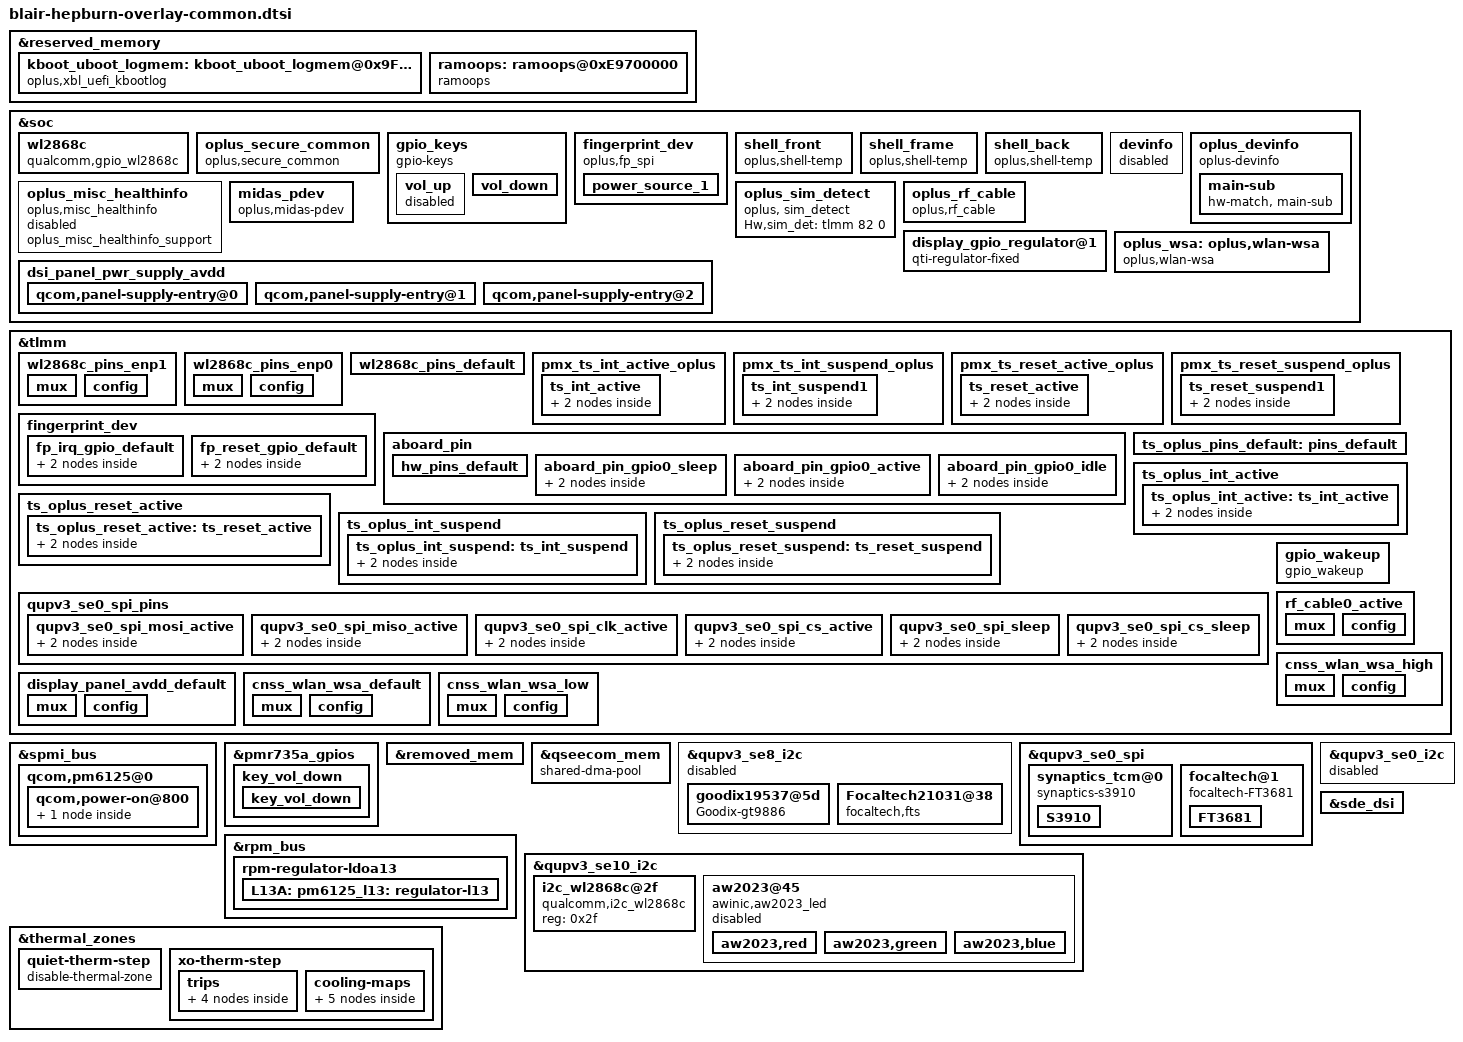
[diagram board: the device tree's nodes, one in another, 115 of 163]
#include "../qcom/blair-qrd-nopmi.dtsi"

/* #ifdef OPLUS_ARCH_EXTENDS */
#include "audio/blair-hepburn-audio.dtsi"
/* #endif OPLUS_ARCH_EXTENDS */
/* DTBO: Platform common generic overlay */

&reserved_memory {
	//xbl_uefi_mem address get from: PcdEmbeddedFdBaseAddress +
	//SERIAL_BUFFER_OFFSET = 0x9FC00000 + 0x3F7000 = 0x9FFF7000
	//kernel boot log: 0x9FE00000~ 0x9FFF6FFF, xbl-uefi log: 0x9FFF7000 ~ 0x9FFFFFFF
	kboot_uboot_logmem: kboot_uboot_logmem@0x9FE00000 {
		reg = <0x0 0x9FE00000 0x0 0x200000>;
		compatible = "oplus,xbl_uefi_kbootlog";
		xbluefi-offset = <0x1F7000>;
		no-map;
	};

	//#if IS_ENABLED(CONFIG_OPLUS_FEATURE_DUMP_DEVICE_INFO)
	ramoops: ramoops@0xE9700000 {
		compatible = "ramoops";
		reg = <0x0 0xE9700000 0x0 0x600000>;  //6M
		record-size  = <0x40000>; //256k
		console-size = <0x40000>; //256k
		ftrace-size  = <0x100000>; //1M
		pmsg-size    = <0x100000>; //1M
		devinfo-size = <0x8000>;  //32k
		ecc-size     = <0x0>;
	 };
};

&soc {
	wl2868c:wl2868c {
		compatible = "qualcomm,gpio_wl2868c";
		pinctrl-names = "default", "wl2868c_gpio_enp0", "wl2868c_gpio_enp1";
		pinctrl-0 = <&wl2868c_pins_default>;
		pinctrl-1 = <&wl2868c_pins_enp0>;
		pinctrl-2 = <&wl2868c_pins_enp1>;
		wl2868c,ldo5-always-on = <1>;
		status = "okay";
	};
};

&tlmm {
	wl2868c_pins_enp1: wl2868c_pins_enp1 {
		mux {
			pins = "gpio58";
			function = "gpio";
		};

		config {
			pins = "gpio58";
			bias-pull-up;
			output-low;
			drive-strength = <2>;
		};
	};

	wl2868c_pins_enp0: wl2868c_pins_enp0 {
		mux {
			pins = "gpio58";
			function = "gpio";
		};

		config {
			pins = "gpio58";
			bias-pull-up;
			output-high;
			drive-strength = <2>;
		};
	};

	wl2868c_pins_default: wl2868c_pins_default {
	};
};

&soc{
	oplus_secure_common {
		compatible = "oplus,secure_common";
		oplus,sec_reg_num = <0x1B405D8>;
		oplus,sec_en_anti_reg = <0x1B401CC>;
		oplus,sec_override1_reg = <0x7860C0>;
		oplus,override1_en_value = <0x1>;
	};
};

&soc {
/*#ifdef OPLUS_FEATURE_TP_BASIC*/
	gpio_keys {
		compatible = "gpio-keys";
		label = "gpio-keys";

		pinctrl-names = "default";
		pinctrl-1 = <&key_vol_down>;
		/* using volume down config update the default value */

		vol_up {
                status="disabled";
		};

		vol_down {
			label = "volume_down";
			gpios = <&pmr735a_gpios 1 GPIO_ACTIVE_LOW>;
			linux,input-type = <1>;
			linux,code = <KEY_VOLUMEDOWN>;
			gpio-key,wakeup;
			debounce-interval = <15>;
			linux,can-disable;
		};
	};
};

&spmi_bus {
	qcom,pm6125@0 {
		qcom,power-on@800 {
/*#ifdef OPLUS_FEATURE_TP_BASIC*/
			qcom,pon_2 {
					qcom,pon-type = <PON_POWER_ON_TYPE_RESIN>;
					qcom,pull-up;
					linux,code = <KEY_VOLUMEUP>;
			};
/*#endif OPLUS_FEATURE_TP_BASIC*/
		};
	};
};

&pmr735a_gpios {
	key_vol_down {
		key_vol_down: key_vol_down {
			pins = "gpio1";
			function = "normal";
			input-enable;
			bias-pull-up;
			power-source = <1>;
		};
	};
};

/* #ifdef OPLUS_FEATURE_CAMERA_COMMON */
//#include "camera/blair-camera-sensor-mtp.dtsi"
/* #endif OPLUS_FEATURE_CAMERA_COMMON */

&soc{

    // #ifdef OPLUS_FEATURE_UFF_FINGERPRINT
	fingerprint_dev {
		status = "ok";
		compatible = "oplus,fp_spi";
		interrupt-parent = <&tlmm>;
		interrupts = <17 0>;
		power-mode = <1> ; /*0: power mode not set, 1: ldo power, 2: gpio power, 3: auto power */
		ldo-supply = <&pm6125_l21>;
		ldo-config = <3300000 3300000 150000>;
		uff,gpio_irq = <&tlmm 17 0x1>;
		uff,gpio_reset = <&tlmm 18 0x0>;
		pinctrl-names = "default";
		pinctrl-0 = <&fp_irq_gpio_default>,<&fp_reset_gpio_default>;
		notify_tpinfo_flag = <1>;
		power-num = <1>;
		power_source_1 {
			power-mode = <1>;
			power-name = "ldo";
			power-config = "ldo-config";
			delay-time = <0>;
		};
	};
	//#endif /*OPLUS_FEATURE_UFF_FINGERPRINT*/

	//#ifdef OPLUS_FEATURE_THERMAL_HORAE
	shell_front {
		compatible = "oplus,shell-temp";
	};

	shell_frame {
		compatible = "oplus,shell-temp";
	};

	shell_back {
		compatible = "oplus,shell-temp";
	};
	//#endif /* OPLUS_FEATURE_THERMAL_HORAE */
};
&removed_mem {
	no-map;
	//reg = <0x0 0xc0000000 0x0 0x5100000>;
	reg = <0x0 0xc0000000 0x0 0x7c00000>;
};

&qseecom_mem {
	compatible = "shared-dma-pool";
	alloc-ranges = <0x0 0x00000000 0x0 0xffffffff>;
	reusable;
	alignment = <0x0 0x400000>;
	//size = <0x0 0x1400000>;
	size = <0x0 0x5000000>;
};

//#ifdef OPLUS_FEATURE_TP_BASIC
&soc {
	devinfo {
		status = "disabled";
	};
	oplus_devinfo {
		compatible = "oplus-devinfo";

		pinctrl-names = "default", "sleep", "active", "idle";
		pinctrl-0 = <&hw_pins_default>;
		pinctrl-1 = <&aboard_pin_gpio0_sleep>;
		pinctrl-2 = <&aboard_pin_gpio0_active>;
		pinctrl-3 = <&aboard_pin_gpio0_idle>;
		main-sub {
			use_tristate_gpio;
			compatible = "hw-match, main-sub";
			aboard-gpio0 = <&tlmm 90 0>;
			aboard-patterns = <0 1 2 2>;	/*0[high-resistance] 1[pull-down] 2[pull-up]*/
			/*main board*/
			match-projects = <22035 22254 22253 22255>;
		};
	};

	oplus_misc_healthinfo:oplus_misc_healthinfo {
		status = "disabled";
		compatible = "oplus,misc_healthinfo";
		oplus_misc_healthinfo_support;
	};

    //#ifdef OPLUS_FEATURE_TP_BASIC
	oplus_sim_detect {
		compatible = "oplus, sim_detect";
		Hw,sim_det = <&tlmm 82 0>;
	};
    //#endif /* OPLUS_FEATURE_TP_BASIC */

    midas_pdev {
        compatible = "oplus,midas-pdev";
    };
};

&tlmm {
	/* add pingrp for touchscreen */
	pmx_ts_int_active_oplus {
		ts_int_active: ts_int_active {
			mux {
				pins = "gpio22";
				function = "gpio";
			};

			config {
				pins = "gpio22";
				drive-strength = <8>;
				bias-disable;
				input-enable;
			};
		};
	};

	pmx_ts_int_suspend_oplus {
		ts_int_suspend1: ts_int_suspend1 {
			mux {
				pins = "gpio22";
				function = "gpio";
			};

			config {
				pins = "gpio22";
				drive-strength = <8>;
				//bias-pull-down;
				bias-pull-up;
				input-enable;
			};
		};
	};

	pmx_ts_reset_active_oplus {
		ts_reset_active: ts_reset_active {
			mux {
				pins = "gpio21";
				function = "gpio";
			};

			config {
				pins = "gpio21";
				drive-strength = <8>;
				output-low;
				bias-disable;
			};
		};
	};

	pmx_ts_reset_suspend_oplus {
		ts_reset_suspend1: ts_reset_suspend1 {
			mux {
				pins = "gpio21";
				function = "gpio";
			};

			config {
				pins = "gpio21";
				drive-strength = <2>;
				bias-pull-down;
			};
		};
	};

	// #ifdef OPLUS_FEATURE_UFF_FINGERPRINT
	fingerprint_dev{
		fp_irq_gpio_default: fp_irq_gpio_default {
			mux {
				pins = "gpio17";
				function = "gpio";
			};
			config {
				pins = "gpio17";
				drive-strength = <2>;
				bias-disable;
				input-enable;
			};
		};

		fp_reset_gpio_default: fp_reset_gpio_default {
			mux {
				pins = "gpio18";
				function = "gpio";
			};
			config {
				pins = "gpio18";
				drive-strength = <2>;
				bias-disable;
				output-low;
			};
		};
	};
	//#endif /*OPLUS_FEATURE_UFF_FINGERPRINT*/

	//#ifdef OPLUS_FEATURE_TP_BASIC
        aboard_pin {
		hw_pins_default:hw_pins_default {
		};

		aboard_pin_gpio0_sleep:aboard_pin_gpio0_sleep {
			mux {
				pins = "gpio90";
				function = "gpio";
			};
			config {
				pins = "gpio90";
				drive-strength = <2>;
				bias-pull-down;
				input-enable;
			};
		};

		aboard_pin_gpio0_active:aboard_pin_gpio0_active {
			mux {
				pins = "gpio90";
				function = "gpio";
			};
			config {
				pins = "gpio90";
				drive-strength = <2>;
				bias-pull-up;
				input-enable;
			};
		};

		aboard_pin_gpio0_idle:aboard_pin_gpio0_idle {
			mux {
				pins = "gpio90";
				function = "gpio";
			};
			config {
				pins = "gpio90";
				bias-disable;
				input-enable;
			};
		};
	};
	//#endif /*OPLUS_FEATURE_TP_BASIC*/

	ts_oplus_pins_default: pins_default {
	};

	ts_oplus_int_active {
        ts_oplus_int_active: ts_int_active {
            mux {
                pins = "gpio21";
                function = "gpio";
            };

            config {
                pins = "gpio21";
                drive-strength = <4>;
                bias-disable;
                input-enable;
            };
        };
    };

    ts_oplus_reset_active {
        ts_oplus_reset_active: ts_reset_active {
            mux {
                pins = "gpio21";
                function = "gpio";
            };

            config {
                pins = "gpio21";
                drive-strength = <4>;
                output-low;
                bias-disable;
            };
        };
    };

	ts_oplus_int_suspend {
        ts_oplus_int_suspend: ts_int_suspend {
            mux {
                pins = "gpio22";
                function = "gpio";
            };

            config {
                pins = "gpio22";
                drive-strength = <4>;
                output-low;
                bias-disable;
            };
        };
    };

	ts_oplus_reset_suspend {
        ts_oplus_reset_suspend: ts_reset_suspend {
            mux {
                pins = "gpio21";
                function = "gpio";
            };

            config {
                pins = "gpio21";
                drive-strength = <4>;
                output-low;
                bias-disable;
            };
        };
    };

};

&qupv3_se8_i2c {
	#address-cells = <1>;
	#size-cells = <0>;

	status = "disabled";

	goodix19537@5d {
		compatible = "Goodix-gt9886";
		reg = <0x5d>;
		chip-name = "GT9886";

		/* Interrupt && Irq-gpio */
		interrupt-parent = <&tlmm>;
		interrupts = <22 0x2002>;

		/* Power Config */
		enable2v8_gpio = <&tlmm 102 0x1>;
		vcc_1v8-supply = <&L13A>;
		vdd_2v8_volt = <3008000>;

		/* Interrupt && Irq-gpio */
		irq-gpio = <&tlmm 22 0x2002>;
		reset-gpio = <&tlmm 21 0x1>;
		pinctrl-names = "default";
		pinctrl-0 = <&ts_int_active &ts_reset_active>;

		touchpanel,max-num-support = <10>;
		touchpanel,tx-rx-num = <16 34>;
		touchpanel,panel-coords = <5400 12000>;
		touchpanel,display-coords = <1080 2400>;
		touchpanel,touchmajor-limit = <0 270>;
		touchpanel,single-optimized-time = <8>;


		vid_len = <2>;
		project_id = <21095>;
		panel_type = <8>;
		tp_type = <8>;
		firmware_name = "0xAA30800";
		platform_support_project = <21095 21295 21296 20826>;
		platform_support_project_dir = <21095 21095 21095 21095>;
		platform_support_project_commandline = "default_commandline","default_commandline","default_commandline","default_commandline";

		/* SW Support Feature Control */
		register-is-16bit;
		black_gesture_support;
		fw_edge_limit_support;
		pressure_report_support;
		charger_pump_support;
		game_switch_support;
		smart_gesture_support;
		fw_update_app_support;
		fingerprint_underscreen_support;
		esd_handle_support;
		goodix_detail_debug_info_support;
		health_monitor_support;
		/*
		 *Virtual Key Config:
		 *1:touchpanel,button-type: <virtualkey_type  supportted_button-map>
		 *virtualkey_type:
		 *Type 1: using board_properties
		 *Type 2: using same IC (button zone&& touch zone are seprate)
		 *Type 3: using diffrent IC (button zone&& touch zone are seprate)
		 *Type 4: No need of virtual key process
		 *supportted_button-map:select|menu|home|back
		 *
		 *2:touchpanel,button-map
		 *type (X1,Y1)(X2,Y2)(X3,Y3)(Width_X,Hight_Y)--Only when button-type is 0
		 */
		touchpanel,button-type = <4>;
		touchpanel.button-TRx = <0 0>;
	};

	Focaltech21031@38 {
		compatible = "focaltech,fts";
		reg = <0x38>;
		chip-name = "FT3518";

		/* Interrupt && Irq-gpio */
		interrupt-parent = <&tlmm>;
		interrupts = <22 0x2002>;

		/* Power Config */
		enable2v8_gpio = <&tlmm 102 0x1>;
		vcc_1v8-supply = <&L13A>;
		vdd_2v8_volt = <3008000>;

		/* Interrupt && Irq-gpio */
                /* Other HW Resource */
		irq-gpio = <&tlmm 22 0x2002>;
		reset-gpio = <&tlmm 21 0x1>;
		pinctrl-names = "default";
		pinctrl-0 = <&ts_int_active &ts_reset_active>;

		touchpanel,max-num-support = <10>;
		touchpanel,tx-rx-num = <16 34>;
		touchpanel,panel-coords = <4320 9600>;
		touchpanel,display-coords = <1080 2400>;
		touchpanel,touchmajor-limit = <0 216>;
		touchpanel,smooth-level = <255 0 10 20 35 50>;
		touchpanel,smooth-level-charging = <255 15 20 25 45 60>;
		touchpanel,sensitive-level = <255 18 14 10 5 0>;

		project_id = <21095>;
		panel_type = <8>;
		tp_type = <8>;
		firmware_name = "0xAA30800";
		platform_support_project = <21095 21295 21296 20826>;
		platform_support_project_dir = <21095 21095 21095 21095>;
		platform_support_project_commandline = "default_commandline","default_commandline","default_commandline","default_commandline";

		/* SW Support Feature Control */
		black_gesture_support;
		fw_edge_limit_support;
		pressure_report_support;
		charger_pump_support;
		game_switch_support;
		smart_gesture_support;
		fw_update_app_support;
		fingerprint_underscreen_support;
		headset_pump_support;
		//esd_handle_support;
		new_set_irq_wake_support;
		irq_need_dev_resume_ok;
		high_resolution_support;
		health_monitor_support;
		/*
		*Virtual Key Config:
		*1:touchpanel,button-type: <virtualkey_type  supportted_button-map>
		*virtualkey_type:
		*Type 1: using board_properties
		*Type 2: using same IC (button zone&& touch zone are seprate)
		*Type 3: using diffrent IC (button zone&& touch zone are seprate)
		*Type 4: No need of virtual key process
		*supportted_button-map:select|menu|home|back
		*
		*2:touchpanel,button-map
		*type (X1,Y1)(X2,Y2)(X3,Y3)(Width_X,Hight_Y)--Only when button-type is 0
		*/
		touchpanel,button-type = <4>;
		touchpanel.button-TRx = <0 0>;
	};
};

&qupv3_se0_spi {
	/delete-property/ pinctrl-0;
	/delete-property/ pinctrl-1;
	pinctrl-0 = <&qupv3_se0_spi_mosi_active>, <&qupv3_se0_spi_miso_active>,
				<&qupv3_se0_spi_clk_active>, <&qupv3_se0_spi_cs_active>;
	pinctrl-1 = <&qupv3_se0_spi_sleep>, <&qupv3_se0_spi_cs_sleep>;
};

&qupv3_se0_i2c {
    status = "disabled";
};

&qupv3_se0_spi {
    status = "ok";
    #address-cells = <1>;
    #size-cells = <0>;
    synaptics_tcm@0{
        status = "ok";
        compatible = "synaptics-s3910";
        reg = <0x0>;
        spi-max-frequency = <12000000>;
        chip-name = "S3910";

        /* Interrupt && Irq-gpio */
		interrupt-parent = <&tlmm>;
        interrupts = <22 0x2008>;
        irq-gpio = <&tlmm 22 0x2008>;
        reset-gpio = <&tlmm 21 0x1>;

        /* Power Config */
        enable2v8_gpio = <&tlmm 102 0x1>;
        //enable1v8_gpio = <&tlmm 97 0x1>;
        //vdd_2v8-supply = <&L3C>;
        vcc_1v8-supply = <&L13A>;
        vdd_2v8_volt = <3300000>;
        /* Other HW Resource */

        pinctrl-names = "default",  "oplus_int_active",
		"oplus_reset_active", "oplus_int_suspend",
		"oplus_reset_suspend";
        pinctrl-0 = <&ts_oplus_pins_default>;
        pinctrl-1 = <&ts_oplus_int_active>;
        pinctrl-2 = <&ts_oplus_reset_active>;
        pinctrl-3 = <&ts_oplus_int_suspend>;
        pinctrl-4 = <&ts_oplus_reset_suspend>;

        touchpanel,max-num-support = <10>;
        touchpanel,tx-rx-num = <16 36>;
        touchpanel,panel-coords = <10800 24120>;
        touchpanel,display-coords = <1080 2412>;
        touchpanel,touchmajor-limit = <128 216>;
        touchpanel,int-mode = <1>; /*0: interrupt and disable, 1:interrupt and not disable*/
        touchpanel,smooth-level = <0 1 2 4 7 9>;
        touchpanel,smooth-level-charging = <0 2 4 7 8 9>;
        touchpanel,sensitive-level = <0 70 55 40 25 10>;
        touchpanel,single-optimized-time = <8>;
        touchpanel,high-frame-rate-time = <60>;

        project_id = <22035>;
        vid_len = <2>;
        touchpanel,tp-index = <0>;
        touchpanel,tp_ic_type = <2>;
        panel_type = <7>;
        tp_type = <7>;
        report_rate_limit = <360>;
        touchpanel,irq_need_dev_resume_time = <250>;
        firmware_name = "0xAA30800";
        // type of tp_dev ,TP-SAMSUNG = 8;
        platform_support_project = <22035 22253 22254>;
        platform_support_project_dir = <22035 22035 22035>;
        platform_support_project_commandline = "mdss_dsi_oplus22035_tm_ili7838a_1080_2412_dsc_cmd","mdss_dsi_oplus22035_tm_ili7838a_1080_2412_dsc_cmd","mdss_dsi_oplus22035_tm_ili7838a_1080_2412_dsc_cmd";

        prevention,curved_screen_V2;
        prevention,grip_disable_level = <6>;
        prevention,updelay_time_ms = <30>;
        prevention,makeup_cnt_weight = <4 1 2 2 2>;
        prevention,large_corner_range = <1200 3000>;
        prevention,large_corner_judge_condition = <500 300 1000 6 6>;
        prevention,trx_reject_condition = <8 7 7>;
        prevention,trx_strict_reject_condition = <8 6 6>;
        prevention,large_judge_time_ms = <500 50 30>;
        prevention,large_exit_condition = <8 8 2>;
        prevention,single_channel_width = <320 320>;
        prevention,normal_tap_condition = <10 300>;
        prevention,long_edge_condition = <200 90 180 80>;
        prevention,long_strict_edge_condition = <160 60>;
        prevention,long_fingerhold_condition = <50 6 4 4>;
        prevention,short_edge_condition = <200 90 180 80>;
        prevention,short_strict_edge_condition = <160 60>;
        prevention,large_strict_exit_condition = <4 4>;
        prevention,top_corner_config = <500 1500 480>;
        prevention,edge_swipe_config = <300 1000>;

        prevention,curved_screen_V4;
        prevention,long_fingerhold_condition2 = <700 2000 0 0>;
        prevention,top_corner_config2 =<3 80 420 1500 0>;
        prevention,hor_long_top_corner_config =<300 2000 0 0>;
        prevention,top_middle_config =<10800 1000 1000 0>;
        prevention,corner_eliminate_point_type =<0 1200 2000 0>;

        /* SW Support Feature Control */
        black_gesture_support;
        sportify_aod_gesture_support;
        pressure_report_support;
        charger_pump_support;
        game_switch_support;
        smart_gesture_support;
        fw_update_app_support;
        fingerprint_underscreen_support;
        freq_hop_simulate_support;
        report_flow_unlock_support;
        screenoff_fingerprint_info_support;
        irq_need_dev_resume_ok;
        enable_point_auto_change;
        kernel_grip_support;
        exception_upload_support;
        //grip_no_driver_support;
        health_monitor_support;
        black_gesture_indep_support;
        snr_read_support;
        /*
         *Virtual Key Config:
         *1:touchpanel,button-type: <virtualkey_type  supportted_button-map>
         *virtualkey_type:
         *Type 1: using board_properties
         *Type 2: using same IC (button zone&& touch zone are seprate)
         *Type 3: using diffrent IC (button zone&& touch zone are seprate)
         *Type 4: No need of virtual key process
         *supportted_button-map:select|menu|home|back
         *
         *2:touchpanel,button-map
         *type (X1,Y1)(X2,Y2)(X3,Y3)(Width_X,Hight_Y)--Only when button-type is 0
         */
        touchpanel,button-type = <4>;
        touchpanel.button-TRx = <0 0>;

        S3910 {
            switch_report_rate;
            report_rate_default = <60>;
            report_rate_game_value = <0x03>;
            fps_report_rate = <60 2 90 3 120 3>;//1:360Hz 2:125Hz 3:240Hz
            fwupdate_bootloader = <1>;
            default_gesture_mask = <8191>;
            normal_config_version = <2>;
        };
    };

    focaltech@1{
        status = "ok";
        compatible = "focaltech-FT3681";
        reg = <0x1>;
        spi-max-frequency = <12000000>;
        chip-name = "FT3681";

        /* Interrupt && Irq-gpio */
		interrupt-parent = <&tlmm>;
        interrupts = <22 0x2002>;
        irq-gpio = <&tlmm 22 0x2002>;
        reset-gpio = <&tlmm 21 0x1>;

        /* Power Config */
        enable2v8_gpio = <&tlmm 102 0x1>;
        //enable1v8_gpio = <&tlmm 97 0x1>;
        //vdd_2v8-supply = <&L3C>;
        vcc_1v8-supply = <&L13A>;
        vdd_2v8_volt = <3300000>;
        /* Other HW Resource */

        pinctrl-names = "default";
        pinctrl-0 = <&ts_oplus_pins_default>;

        touchpanel,max-num-support = <10>;
        touchpanel,tx-rx-num = <16 36>;
        touchpanel,panel-coords = <8640 19296>;
        touchpanel,display-coords = <1080 2412>;
        touchpanel,touchmajor-limit = <128 216>;
        touchpanel,smooth-level = <0 110 115 120 140 155>;
        touchpanel,smooth-level-charging = <0 100 110 115 120 140>;
        touchpanel,sensitive-level = <0 20 17 15 13 10>;
        touchpanel,single-optimized-time = <8>;
        touchpanel,high-frame-rate-time = <60>;

        project_id = <22035>;
        vid_len = <2>;
        touchpanel,tp-index = <0>;
        touchpanel,tp_ic_type = <2>;
        panel_type = <3 3 3 18 18 18>;
        touchpanel,irq_need_dev_resume_time = <250>;
        //tp_type = <3>;
        report_rate_limit = <360>;
        firmware_name = "0xAA30800","0xAA30800","0xAA30800","0xAA30801","0xAA30801","0xAA30801";
        // type of tp_dev ,TP-SAMSUNG = 8;
        platform_support_project = <22035 22253 22254>;
        platform_support_project_dir = <22035 22035 22035>;
        platform_support_project_commandline = "mdss_dsi_oplus22035_boe_nt37705_1080_2412_dsc_cmd","mdss_dsi_oplus22035_boe_nt37705_1080_2412_dsc_cmd","mdss_dsi_oplus22035_boe_nt37705_1080_2412_dsc_cmd","mdss_dsi_oplus22035_visionox_ili7838a_1080_2412_dsc_cmd","mdss_dsi_oplus22035_visionox_ili7838a_1080_2412_dsc_cmd","mdss_dsi_oplus22035_visionox_ili7838a_1080_2412_dsc_cmd";

        prevention,curved_screen_V2;
        prevention,grip_disable_level = <6>;
        prevention,updelay_time_ms = <30>;
        prevention,makeup_cnt_weight = <4 1 2 2 2>;
        prevention,large_corner_range = <960 2400>;
        prevention,large_corner_judge_condition = <500 300 800 6 6>;
        prevention,trx_reject_condition = <8 7 7>;
        prevention,trx_strict_reject_condition = <7 6 6>;
        prevention,large_judge_time_ms = <500 50 30>;
        prevention,large_exit_condition = <15 12 2>;
        prevention,single_channel_width = <256 256>;
        prevention,normal_tap_condition = <10 300>;
        prevention,long_edge_condition = <230 100 180 80>;
        prevention,long_strict_edge_condition = <170 80>;
        prevention,long_fingerhold_condition = <50 6 4 4>;
        prevention,short_edge_condition = <230 100 180 120>;
        prevention,short_strict_edge_condition = <160 60>;
        prevention,large_strict_exit_condition = <5 5>;
        prevention,top_corner_config = <400 1200 380>;
        prevention,edge_swipe_config = <240 800>;

        prevention,curved_screen_V4;
        prevention,long_fingerhold_condition2 = <560 1600 0 0>;
        prevention,top_corner_config2 =<3 80 420 1200 0>;
        prevention,hor_long_top_corner_config =<240 1600 0 0>;
        prevention,top_middle_config =<8640 800 800 0>;
        prevention,corner_eliminate_point_type =<0 960 1600 0>;

        /* SW Support Feature Control */
        black_gesture_support;
        sportify_aod_gesture_support;
        pressure_report_support;
        charger_pump_support;
        game_switch_support;
        smart_gesture_support;
        fw_update_app_support;
        fingerprint_underscreen_support;
        freq_hop_simulate_support;
        report_flow_unlock_support;
        screenoff_fingerprint_info_support;
        irq_need_dev_resume_ok;
        //enable_point_auto_change;
        kernel_grip_support;
        exception_upload_support;
        //grip_no_driver_support;
        health_monitor_support;
        black_gesture_indep_support;
        temperature_detect_shellback_support;
        snr_read_support;
        disable_suspend_irq_handler_support;
        /*
         *Virtual Key Config:
         *1:touchpanel,button-type: <virtualkey_type  supportted_button-map>
         *virtualkey_type:
         *Type 1: using board_properties
         *Type 2: using same IC (button zone&& touch zone are seprate)
         *Type 3: using diffrent IC (button zone&& touch zone are seprate)
         *Type 4: No need of virtual key process
         *supportted_button-map:select|menu|home|back
         *
         *2:touchpanel,button-map
         *type (X1,Y1)(X2,Y2)(X3,Y3)(Width_X,Hight_Y)--Only when button-type is 0
         */
        touchpanel,button-type = <4>;
        touchpanel.button-TRx = <0 0>;

		FT3681 {
			switch_report_rate;
			report_rate_default = <60>;
			report_rate_game_value = <0x02>;
		};
    };




};

&rpm_bus {
	rpm-regulator-ldoa13 {
		status = "okay";
		/delete-property/proxy-supply;
		L13A: pm6125_l13: regulator-l13 {
			regulator-min-microvolt = <1650000>;
			regulator-max-microvolt = <1980000>;
			qcom,init-voltage = <1650000>;
			/delete-property/qcom,proxy-consumer-enable;
			/delete-property/qcom,proxy-consumer-current;
			status = "okay";
		};
	};
};

&tlmm {
	qupv3_se0_spi_pins: qupv3_se0_spi_pins {
		qupv3_se0_spi_mosi_active: qupv3_se0_spi_mosi_active {
			mux {
				pins = "gpio1";
				function = "qup00";
			};

			config {
				pins = "gpio1";
				drive-strength = <4>;
				bias-disable;
			};
		};

		qupv3_se0_spi_miso_active: qupv3_se0_spi_miso_active {
			mux {
				pins = "gpio0";
				function = "qup00";
			};

			config {
				pins = "gpio0";
				drive-strength = <4>;
				bias-disable;
			};
		};

		qupv3_se0_spi_clk_active: qupv3_se0_spi_clk_active {
			mux {
				pins = "gpio2";
				function = "qup00";
			};

			config {
				pins = "gpio2";
				drive-strength = <4>;
				bias-disable;
			};
		};

		qupv3_se0_spi_cs_active: qupv3_se0_spi_cs_active {
			mux {
				pins = "gpio3";
				function = "qup00";
			};

			config {
				pins = "gpio3";
				drive-strength = <4>;
				bias-disable;
			};
		};

		qupv3_se0_spi_sleep: qupv3_se0_spi_sleep {
			mux {
				pins = "gpio3";
				function = "gpio";
			};

			config {
				pins = "gpio3";
				drive-strength = <4>;
				bias-disable;
			};
		};

		qupv3_se0_spi_cs_sleep: qupv3_se0_spi_cs_sleep {
			mux {
				pins = "gpio3";
				function = "gpio";
			};

			config {
				pins = "gpio3";
				drive-strength = <4>;
				bias-disable;
				output-high;
			};
		};
	};
//#endif /*OPLUS_FEATURE_TP_BASIC*/
};

&qupv3_se10_i2c {
	#address-cells = <1>;
	#size-cells = <0>;

	status = "okay";

	i2c_wl2868c@2f{
		compatible = "qualcomm,i2c_wl2868c";
		reg = <0x2f>;
		status = "okay";
	};

	aw2023@45 {
		status = "disabled";
		compatible = "awinic,aw2023_led";
		reg = <0x45>;
		vcc-supply = <&L9A>;

		aw2023,red {
			aw2023,name = "red";
			aw2023,id = <0>;
			aw2023,imax = <1>;
			aw2023,led_default_trigger = "none";
			aw2023,brightness = <3>;
			aw2023,max-brightness = <15>;
			aw2023,rise-time-ms = <6>;
			aw2023,hold-time-ms = <0>;
			aw2023,fall-time-ms = <6>;
			aw2023,off-time-ms = <4>;
		};

		aw2023,green {
			aw2023,name = "green";
			aw2023,id = <1>;
			aw2023,imax = <1>;
			aw2023,led_default_trigger = "none";
			aw2023,brightness = <3>;
			aw2023,max-brightness = <15>;
			aw2023,rise-time-ms = <6>;
			aw2023,hold-time-ms = <0>;
			aw2023,fall-time-ms = <6>;
			aw2023,off-time-ms = <4>;
		};

		aw2023,blue {
			aw2023,name = "blue";
			aw2023,id = <2>;
			aw2023,imax = <1>;
			aw2023,led_default_trigger = "none";
			aw2023,brightness = <3>;
			aw2023,max-brightness = <15>;
			aw2023,rise-time-ms = <6>;
			aw2023,hold-time-ms = <0>;
			aw2023,fall-time-ms = <6>;
			aw2023,off-time-ms = <4>;
		};
	};
};

&tlmm {
	//Liu.Xu 2021/0926 add for disable wake-up function of NC-GPIO
	/* delete gpio114 for wifi ant swap */
	gpio_wakeup: gpio_wakeup {
		compatible = "gpio_wakeup";
		gpio_table = <6 12 33 38 56 57 88 90 91 92 99 108 113 115 116
                              7 8 9 48 51 59 84 85 86 107 117 118 152 153 154 155>;
	};
};

//Wei.Tang 2021/09/23 modify for rf_cable
&tlmm {
	rf_cable0_active: rf_cable0_active {
		mux {
			pins = "gpio24";
			function = "gpio";
		};
		config {
			pins = "gpio24";
			drive-strength = <2>;
			input-enable;
			bias-pull-up;
		};
	};
};

&soc {
	oplus_rf_cable {
		compatible = "oplus,rf_cable";
		interrupt-parent = <&tlmm>;
		rf_cable_support_num = <1>;
		rf,cable0-gpio = <&tlmm 24 0>;
		rf,cable-support-timer = <0>;
		pinctrl-names = "rf_cable_active";
		pinctrl-0 = <&rf_cable0_active>;
	};
};

//#ifdef OPLUS_FEATURE_CHG_BASIC
#include "charge/oplus_charge_hepburn.dtsi"
//#endif

&tlmm {
	/* blair_reserved_gpios[] = {13, 14, 15, 16, 48, 56, 57, -1}; */
	/* delete gpio45 gpio46 */
	gpios = /bits/ 16 <
			0 1 2 3 4 5 6 7 8 9
			10 11 12             17 18 19
			20 21 22 23 24 25 26 27 28 29
			30 31 32 33 34 35 36 37 38 39
			40 41 42 43 44       47    49
			50 51 52 53 54 55       58 59
			60 61 62 63 64 65 66 67 68 69
			70 71 72 73 74 75 76 77 78 79
			80 81 82 83 84 85 86 87 88 89
			90 91 92 93 94 95 96 97 98 99
			100 101 102 103 104 105 106 107 108 109
			110 111 112 113 114 115 116 117 118 119
			120 121 122 123 124 125 126 127 128 129
			130 131 132 133 134 135 136 137 138 139
			140 141 142 143 144 145 146 147 148 149
			150 151 152 153 154 155 156
			>;
};

//#ifdef OPLUS_TEMP_NTC
&thermal_zones {
	quiet-therm-step {
		disable-thermal-zone;
	};

	xo-therm-step {
		polling-delay-passive = <2000>;
		polling-delay = <0>;
		thermal-governor = "step_wise";
		thermal-sensors = <&pm6125_adc_tm ADC5_XO_THERM_100K_PU>;

		trips {
			xo_gold_trip: xo-gold-trip {
				temperature = <48000>;
				hysteresis = <0>;
				type = "passive";
			};

			xo_gpu_trip: xo-gpu-trip {
				temperature = <48000>;
				hysteresis = <0>;
				type = "passive";
			};

			xo_silver_trip: xo-silver-trip {
				temperature = <50000>;
				hysteresis = <0>;
				type = "passive";
			};

			xo_cx_trip: xo-cx-trip {
				temperature = <55000>;
				hysteresis = <5000>;
				type = "passive";
			};
		};

		cooling-maps {
			cdsp-cdev {
				trip = <&xo_cx_trip>;
				cooling-device = <&cdsp_sw 4 4>;
			};

			gpu-cdev0 {
				trip = <&xo_gpu_trip>;
				/* throttle to 650000000Hz */
				cooling-device = <&msm_gpu THERMAL_NO_LIMIT
							(THERMAL_MAX_LIMIT-3)>;
			};

			gpu-cdev1 {
				trip = <&xo_cx_trip>;
				/* throttle to 390000000Hz */
				cooling-device = <&msm_gpu (THERMAL_MAX_LIMIT-1)
							(THERMAL_MAX_LIMIT-1)>;
			};

			silver-cdev {
				trip = <&xo_silver_trip>;
				/* throttle to 1516800KHz */
				cooling-device = <&CPU0 THERMAL_NO_LIMIT
							(THERMAL_MAX_LIMIT-6)>;
			};

			gold-cdev {
				trip = <&xo_gold_trip>;
				/* throttle to 2054400KHz */
				cooling-device = <&CPU6 THERMAL_NO_LIMIT
							(THERMAL_MAX_LIMIT-8)>;
			};
		};
	};
};


&tlmm {
	display_panel_avdd_default {
		mux {
			pins = "gpio101";
			function = "gpio";
		};

		config {
			pins = "gpio101";
			drive-strength = <8>;
			bias-disable = <0>;
			output-high;
		};
	};
};

&soc {
	display_gpio_regulator@1 {
		compatible = "qti-regulator-fixed";
		regulator-name = "display_panel_avdd";
		regulator-min-microvolt = <3000000>;
		regulator-max-microvolt = <3000000>;
		regulator-enable-ramp-delay = <233>;
		gpio = <&tlmm 101 0>;
		enable-active-high;
		regulator-boot-on;
		proxy-supply = <&display_panel_avdd>;
		qcom,proxy-consumer-enable;
		pinctrl-names = "default";
		pinctrl-0 = <&display_panel_avdd_default>;
	};

	dsi_panel_pwr_supply_avdd {
		#size-cells = <0>;
		#address-cells = <1>;

		qcom,panel-supply-entry@0 {
			reg = <0>;
			qcom,supply-name = "vddio";
			qcom,supply-min-voltage = <1800000>;
			qcom,supply-max-voltage = <1800000>;
			qcom,supply-enable-load = <62000>;
			qcom,supply-disable-load = <80>;
		};

                qcom,panel-supply-entry@1 {
			reg = <1>;
			qcom,supply-name = "vddr";
			qcom,supply-min-voltage = <1230000>;
			qcom,supply-max-voltage = <1230000>;
			qcom,supply-enable-load = <62000>;
			qcom,supply-disable-load = <0>;
			qcom,supply-post-on-sleep = <5>;
			qcom,supply-pre-off-sleep = <5>;
		};
		qcom,panel-supply-entry@2 {
			reg = <2>;
			qcom,supply-name = "avdd";
			qcom,supply-min-voltage = <3000000>;
			qcom,supply-max-voltage = <3000000>;
			qcom,supply-enable-load = <857000>;
			qcom,supply-disable-load = <0>;
			qcom,supply-post-on-sleep = <10>;
		};

	};
};
&sde_dsi {
	vddio-supply = <&L9A>;
	vddr-supply = <&L3A>;
};

&soc {
    //#ifdef OPLUS_FEATURE_WIFI_SMART_ANTENNA
    oplus_wsa:oplus,wlan-wsa {
        compatible = "oplus,wlan-wsa";
        wlan-wsa-gpio = <&tlmm 114 0>;
        pinctrl-names = "default", "cnss_wlan_wsa_high", "cnss_wlan_wsa_low";
        pinctrl-0 = <&cnss_wlan_wsa_default>;
        pinctrl-1 = <&cnss_wlan_wsa_high>;
        pinctrl-2 = <&cnss_wlan_wsa_low>;
        status = "okay";
    };
    //#endif
};

//#ifdef OPLUS_FEATURE_WIFI_SMART_ANTENNA
&tlmm {
   cnss_wlan_wsa_default: cnss_wlan_wsa_default {
       mux {
           pins = "gpio114";
           function = "gpio";
       };

       config {
           pins = "gpio114";
           drive-strength = <8>;
           output-high;
           bias-pull-up;
       };
   };

   cnss_wlan_wsa_high: cnss_wlan_wsa_high {
       mux {
           pins = "gpio114";
           function = "gpio";
       };

       config {
           pins = "gpio114";
           drive-strength = <2>;
           output-high;
           bias-pull-up;
       };
   };

   cnss_wlan_wsa_low: cnss_wlan_wsa_low {
       mux {
           pins = "gpio114";
           function = "gpio";
       };

       config {
           pins = "gpio114";
           drive-strength = <2>;
           output-low;
           bias-pull-up;
       };
   };
};
//#endif
//#endif
